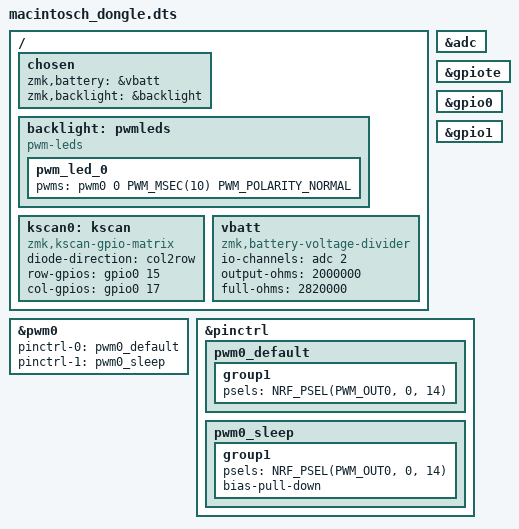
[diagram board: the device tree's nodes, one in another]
/*
 * Copyright (c) 2023 ZitaoTech
 *
 * SPDX-License-Identifier: MIT
 */

#include "central.dtsi"

/ {
    chosen {
        zmk,battery = &vbatt;
        zmk,backlight = &backlight;
    };

    backlight: pwmleds {
        compatible = "pwm-leds";
        pwm_led_0 {
            pwms = <&pwm0 0 PWM_MSEC(10) PWM_POLARITY_NORMAL>;
        };
    };

    kscan0: kscan {
        compatible = "zmk,kscan-gpio-matrix";
        diode-direction = "col2row";
        row-gpios
            = <&gpio0 15 (GPIO_ACTIVE_HIGH | GPIO_PULL_DOWN)>
            ;
        col-gpios
            = <&gpio0 17  GPIO_ACTIVE_HIGH>
            ;
    };


    vbatt: vbatt {
        compatible = "zmk,battery-voltage-divider";
        io-channels = <&adc 2>;
        output-ohms = <2000000>;
        full-ohms = <2820000>;  // 2000000 + 820000
    };
};

&adc {
    status = "okay";
};

&gpiote {
    status = "okay";
};

&gpio0 {
    status = "okay";
};

&gpio1 {
    status = "okay";
};

&pwm0 {
    status = "okay";
    pinctrl-0 = <&pwm0_default>;
    pinctrl-1 = <&pwm0_sleep>;
    pinctrl-names = "default", "sleep";
};

&pinctrl {

    pwm0_default:pwm0_default{
        group1{
            psels = <NRF_PSEL(PWM_OUT0, 0, 14)>; // Backlight for backlight.c unreal
        };
    };

    pwm0_sleep: pwm0_sleep {
        group1 {
            psels = <NRF_PSEL(PWM_OUT0, 0, 14)>;
            bias-pull-down;
        };
    };

};
